# uart_16550_main_wo: IP-XACT component
VLNV tenstorrent.com:ocah:uart_16550_main_wo:1.0

## Address spaces and blocks
uart_16550_main_wo_mmap.uart_16550_main_wo: base 'h0, range 'hc, width 32

## Registers
Registers are 32-bit, write-only, reset 0x0 unless marked. A register's access mark holds for its fields unless they carry their own. Offsets are from the block's base; lines under a group give offsets from that group; [hi:lo] are bit positions; {n}, {i} and the like mark numbered series; 'fields as' and 'values as' point back to an identical list; <NAME> marks a mode.

## uart_16550_main_wo_mmap.uart_16550_main_wo — Contains the write-only registers. THR is accessible only when `LCR.DLAB = 0`; FCR is writable for either `LCR.DLAB` value.
Base 0x00000000
0x00 THR — Transmitter Holding Register
  [7:0] DATA — Transmit Data. Holds a character to be transmitted. If FIFOs are enabled, this field points to the top of the TX FIFO. Otherwise, this field points to a single-byte Transmitter Holding Register.
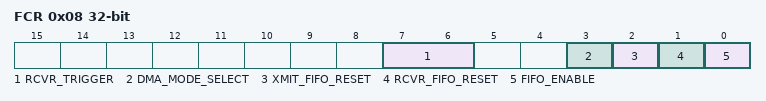
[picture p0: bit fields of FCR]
0x08 FCR — FIFO Control Register
  [7:6] RCVR_TRIGGER — Receiver FIFO Trigger Level (Least Significant 2 Bits). To configure the most significant 2 bits, use the `ECR.RCVR_TRIGGER_MS2B` register field. The configurations for the trigger levels are: * `0x0` - 1 character * `0x1` - 4 characters * `0x2` - 8 characters * `0x3` - 14 characters * `0x4` - 32 characters * `0x5` - 64 characters * `0x6` - 128 characters * `0x7` - 256 characters * `0x8` - 512 characters * `0x9` - 1024 characters * `0xA` - 2048 characters * `0xB` - 4096 characters The Received Data Ready interrupt asserts while the receive FIFO holds at least the selected number of characters. A level above the receive FIFO depth, and any combined value above `0xB`, never asserts it.
  [3] DMA_MODE_SELECT — DMA mode select: * `0` - DMA Mode 0 * `1` - DMA Mode 1
  [2] XMIT_FIFO_RESET — Transmitter FIFO Reset. Writing `1` clears the TX FIFO.
  [1] RCVR_FIFO_RESET — Receiver FIFO Reset. Writing `1` clears the RX FIFO.
  [0] FIFO_ENABLE — FIFO Enable. When set, enables the TX and RX FIFOs (FIFO Mode). When unset, disables the FIFOs (Non-FIFO Mode).

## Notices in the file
SPDX-License-Identifier: Apache-2.0
SPDX-FileCopyrightText: 2026 Tenstorrent USA, Inc.
